AUTOSAR XML (schema 4-3-0)
package /Example
  client server interface MyInterface1
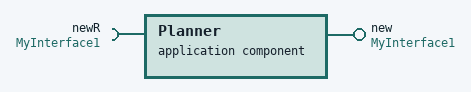
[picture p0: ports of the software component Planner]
  application sw component type Planner
    provide port new: provided-interface=MyInterface1
    require port newR: required-interface=MyInterface1
package /p1
  application sw component type Planner_COPIED_AtLastTransformation
    require port Modified_Cp_Changed: required-interface=SensorFusion, t1=t2=Val
  sender receiver interface SensorFusion
  application sw component type PlannerCp
    require port Modified: required-interface=sp
  client server interface ActuatorControl
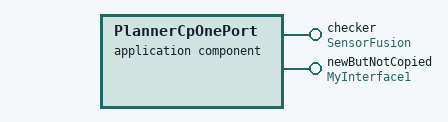
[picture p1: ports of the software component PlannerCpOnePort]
  application sw component type PlannerCpOnePort
    provide port checker: provided-interface=SensorFusion
    provide port newButNotCopied: provided-interface=MyInterface1
package /p1/p2/p3
  sender receiver interface Sr
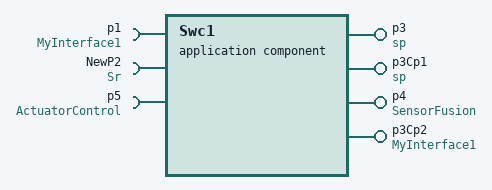
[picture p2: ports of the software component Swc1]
  application sw component type Swc1
    require port p1: required-interface=MyInterface1
    require port NewP2: required-interface=Sr
    provide port p3: provided-interface=sp
    provide port p3Cp1: provided-interface=sp
    provide port p4: provided-interface=SensorFusion
    require port p5: required-interface=ActuatorControl
    provide port p3Cp2: provided-interface=MyInterface1
  client server interface sp
